# npcx9m6f register map
Registers are 8-bit, read-write, no defined reset value unless marked. A register's access mark holds for its fields unless they carry their own. Offsets are from the block's base; [hi:lo] are bit positions; {n}, {i} and the like mark numbered series.

## KBS — Keyboard Scan Modules
Base 0x400A3000
0x04 KBSIN
0x05 KBSINPU
0x06 KBSOUT0 16-bit
0x08 KBSOUT1 16-bit
0x0A KBS_BUF_INDX
  [4:0] KBS_BUF_INDX
0x0B KBS_BUF_DATA
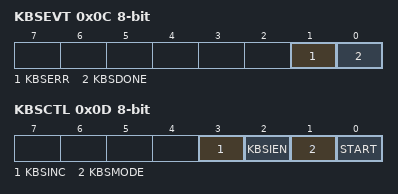
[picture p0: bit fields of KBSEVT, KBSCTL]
0x0C KBSEVT
  [1] KBSERR, [0] KBSDONE
0x0D KBSCTL
  [3] KBSINC, [2] KBSIEN, [1] KBSMODE, [0] START
0x0E KBS_CFG_INDX
  [4:0] KBS_CFG_INDX
0x0F KBS_CFG_DATA

## SPIP — SPI Peripheral Interface Module
Base 0x400D2000
0x00 SPIP_DATA 16-bit
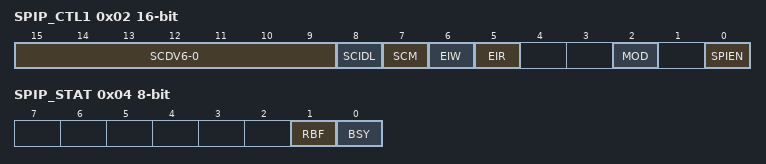
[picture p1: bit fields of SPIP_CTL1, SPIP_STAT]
0x02 SPIP_CTL1 16-bit
  [15:9] SCDV6-0, [8] SCIDL, [7] SCM, [6] EIW, [5] EIR, [2] MOD, [0] SPIEN
0x04 SPIP_STAT
  [1] RBF, [0] BSY
0x08 SPIP_TEST 16-bit
  [0] TB
0x0E SPIP_VER

## SPIP2 — SPI Peripheral Interface Module
Base 0x400D0000
Registers as SPIP (with SPIP read as SPIP2).

## SHI — Serial Host Interface Module
Base 0x4000F000
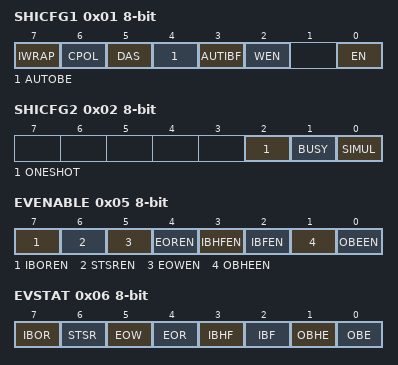
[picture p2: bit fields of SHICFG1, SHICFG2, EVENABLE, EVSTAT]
0x01 SHICFG1
  [7] IWRAP, [6] CPOL, [5] DAS, [4] AUTOBE, [3] AUTIBF, [2] WEN, [0] EN
0x02 SHICFG2
  [2] ONESHOT, [1] BUSY, [0] SIMUL
0x05 EVENABLE
  [7] IBOREN, [6] STSREN, [5] EOWEN, [4] EOREN, [3] IBHFEN, [2] IBFEN, [1] OBHEEN, [0] OBEEN
0x06 EVSTAT
  [7] IBOR, [6] STSR, [5] EOW, [4] EOR, [3] IBHF, [2] IBF, [1] OBHE, [0] OBE
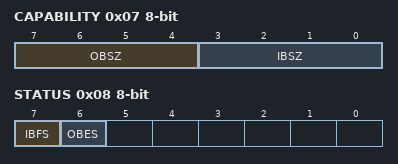
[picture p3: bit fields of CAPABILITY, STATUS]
0x07 CAPABILITY
  [7:4] OBSZ, [3:0] IBSZ
0x08 STATUS
  [7] IBFS, [6] OBES
0x0A IBUFSTAT
0x0B OBUFSTAT

## OBUF0-7
Base 0x4000F000
{0x20+i} OBUF{i:02} (i=0..7)

## OBUF8-15
Base 0x4000F000
{0x20+i} OBUF{i:02} (i=8..15)

## OBUF16-23
Base 0x4000F000
{0x20+i} OBUF{i} (i=16..23)

## OBUF24-31
Base 0x4000F000
{0x20+i} OBUF{i} (i=24..31)

## OBUF32-39
Base 0x4000F000
{0x20+i} OBUF{i} (i=32..39)

## OBUF40-47
Base 0x4000F000
{0x20+i} OBUF{i} (i=40..47)

## OBUF48-55
Base 0x4000F000
{0x20+i} OBUF{i} (i=48..55)

## OBUF56-63
Base 0x4000F000
{0x20+i} OBUF{i} (i=56..63)

## IBUF0-7
Base 0x4000F000
{0x60+i} IBUF{i:02} (i=0..7)

## IBUF8-15
Base 0x4000F000
{0x60+i} IBUF{i:02} (i=8..15)

## IBUF16-23
Base 0x4000F000
{0x60+i} IBUF{i} (i=16..23)

## IBUF24-31
Base 0x4000F000
{0x60+i} IBUF{i} (i=24..31)

## IBUF32-39
Base 0x4000F000
{0x60+i} IBUF{i} (i=32..39)

## IBUF40-47
Base 0x4000F000
{0x60+i} IBUF{i} (i=40..47)

## IBUF48-55
Base 0x4000F000
{0x60+i} IBUF{i} (i=48..55)

## IBUF56-63
Base 0x4000F000
{0x60+i} IBUF{i} (i=56..63)

## BBRM — Battery-Backed RAM
Base 0x400AF000
0x00 BKUP_STS
  [7] IBBR

## AES — AES Module
Base 0x40002000
0x00 AES_STS 32-bit
  [0] DONE
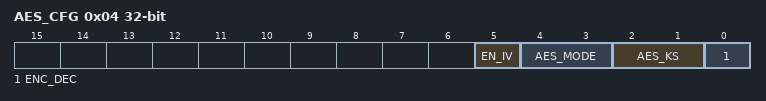
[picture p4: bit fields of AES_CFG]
0x04 AES_CFG 32-bit
  [5] EN_IV, [4:3] AES_MODE, [2:1] AES_KS, [0] ENC_DEC
0x08 AES_VER 32-bit
  [7:0] AES_VER
{0x10+4i} AES_DI_{i} 32-bit (i=0..3)
{0x20+4i} AES_IV_{i} 32-bit (i=0..3)
{0x30+4i} AESKEY_{i} 32-bit (i=0..7)
0x50 AES_DO_3 32-bit
0x54 AES_DO_2 32-bit
0x58 AES_DO_1 32-bit
0x5C AES_DO_0 32-bit
0x60 AES_CTL 32-bit
  [0] Start

## PKA — Public Key Accelerator Module
Base 0x40001000
0x14 PKA_VER 32-bit
  [7:0] PKA_VER
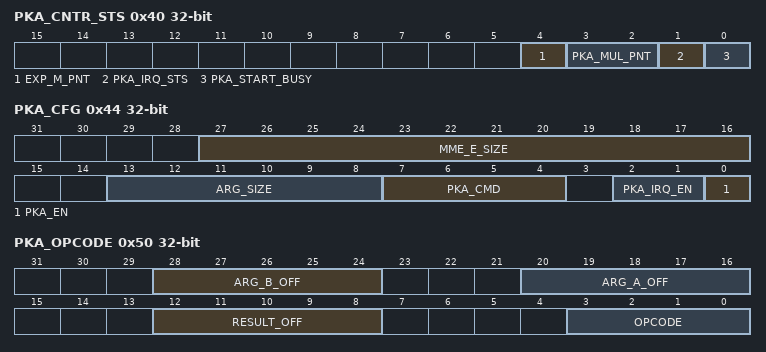
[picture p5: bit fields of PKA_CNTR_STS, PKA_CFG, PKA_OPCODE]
0x40 PKA_CNTR_STS 32-bit
  [4] EXP_M_PNT, [3:2] PKA_MUL_PNT, [1] PKA_IRQ_STS, [0] PKA_START_BUSY
0x44 PKA_CFG 32-bit
  [27:16] MME_E_SIZE, [13:8] ARG_SIZE, [7:4] PKA_CMD, [2:1] PKA_IRQ_EN, [0] PKA_EN
0x48 MME_J0 32-bit
0x50 PKA_OPCODE 32-bit
  [28:24] ARG_B_OFF, [20:16] ARG_A_OFF, [12:8] RESULT_OFF, [3:0] OPCODE

## SHA1-2 — SHA1-2 Hash Engine Module
Base 0x40002000
0x00 HASH_DATA_IN 32-bit
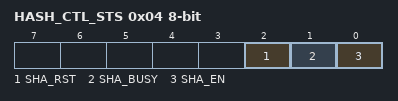
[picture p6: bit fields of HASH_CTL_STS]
0x04 HASH_CTL_STS
  [2] SHA_RST, [1] SHA_BUSY, [0] SHA_EN
0x08 HASH_CFG
  [0] SHA1_SHA2
0x0C HASH_VER
{0x20+4i} HASH_DIG_H_{i} 32-bit (i=0..7)

## RNG — Random Number Generator Module
Base 0x400D9000
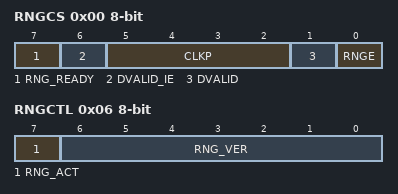
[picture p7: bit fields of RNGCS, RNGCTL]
0x00 RNGCS
  [7] RNG_READY, [6] DVALID_IE, [5:2] CLKP, [1] DVALID, [0] RNGE
0x02 RNGD
0x06 RNGCTL
  [7] RNG_ACT, [6:0] RNG_VER
